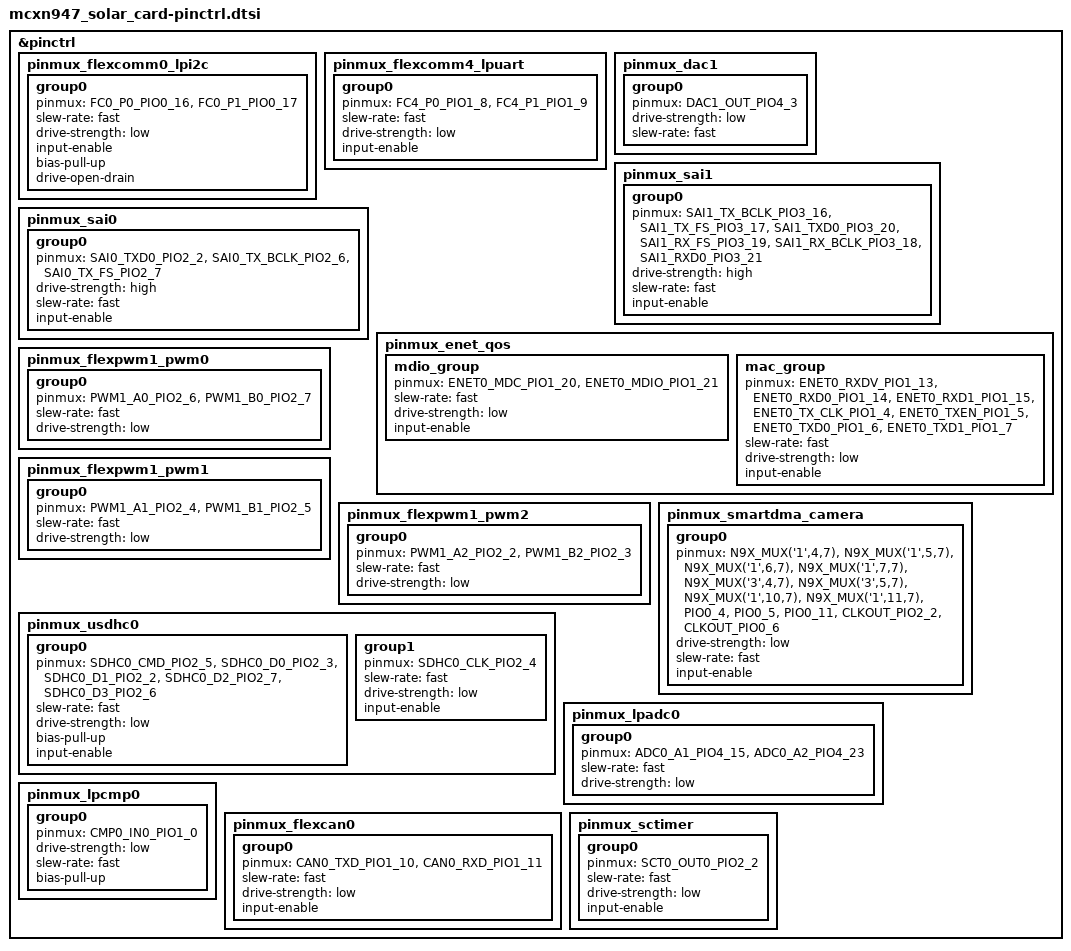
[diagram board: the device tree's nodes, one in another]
/*
 * Copyright 2024 NXP
 * SPDX-License-Identifier: Apache-2.0
 */


#include <nxp/mcx/MCXN947VDF-pinctrl.h>

&pinctrl {
	pinmux_flexcomm0_lpi2c: pinmux_flexcomm0_lpi2c {
		group0 {
			pinmux = <FC0_P0_PIO0_16>,
				<FC0_P1_PIO0_17>;
			slew-rate = "fast";
			drive-strength = "low";
			input-enable;
			bias-pull-up;
			drive-open-drain;
		};
	};

	pinmux_flexcomm4_lpuart: pinmux_flexcomm4_lpuart {
		group0 {
			pinmux = <FC4_P0_PIO1_8>,
				<FC4_P1_PIO1_9>;
			slew-rate = "fast";
			drive-strength = "low";
			input-enable;
		};
	};

	pinmux_dac1: pinmux_dac1 {
		group0 {
			pinmux = <DAC1_OUT_PIO4_3>;
			drive-strength = "low";
			slew-rate = "fast";
		};
	};

	pinmux_sai1: pinmux_sai1 {
		group0 {
			pinmux = <SAI1_TX_BCLK_PIO3_16>,
				<SAI1_TX_FS_PIO3_17>,
				<SAI1_TXD0_PIO3_20>,
				<SAI1_RX_FS_PIO3_19>,
				<SAI1_RX_BCLK_PIO3_18>,
				<SAI1_RXD0_PIO3_21>;
			drive-strength = "high";
			slew-rate = "fast";
			input-enable;
		};
	};

	pinmux_sai0: pinmux_sai0 {
		group0 {
			pinmux = <SAI0_TXD0_PIO2_2>,
				<SAI0_TX_BCLK_PIO2_6>,
				<SAI0_TX_FS_PIO2_7>;
			drive-strength = "high";
			slew-rate = "fast";
			input-enable;
		};
	};

	pinmux_enet_qos: pinmux_enet_qos {
		mdio_group {
			pinmux = <ENET0_MDC_PIO1_20>,
				<ENET0_MDIO_PIO1_21>;
			slew-rate = "fast";
			drive-strength = "low";
			input-enable;
		};
		mac_group {
			pinmux = <ENET0_RXDV_PIO1_13>,
				<ENET0_RXD0_PIO1_14>,
				<ENET0_RXD1_PIO1_15>,
				<ENET0_TX_CLK_PIO1_4>,
				<ENET0_TXEN_PIO1_5>,
				<ENET0_TXD0_PIO1_6>,
				<ENET0_TXD1_PIO1_7>;
			slew-rate = "fast";
			drive-strength = "low";
			input-enable;
		};
	};

	pinmux_flexpwm1_pwm0: pinmux_flexpwm1_pwm0 {
		group0 {
			pinmux = <PWM1_A0_PIO2_6>,
				<PWM1_B0_PIO2_7>;
			slew-rate = "fast";
			drive-strength = "low";
		};
	};

	pinmux_flexpwm1_pwm1: pinmux_flexpwm1_pwm1 {
		group0 {
			pinmux = <PWM1_A1_PIO2_4>,
				<PWM1_B1_PIO2_5>;
			slew-rate = "fast";
			drive-strength = "low";
		};
	};

	pinmux_flexpwm1_pwm2: pinmux_flexpwm1_pwm2 {
		group0 {
			pinmux = <PWM1_A2_PIO2_2>,
				<PWM1_B2_PIO2_3>;
			slew-rate = "fast";
			drive-strength = "low";
		};
	};

	pinmux_smartdma_camera: pinmux_smartdma_camera {
		group0 {
			/*
			 * SmartDMA pinmux is not defined by SOC header, so
			 * we encode it manually
			 */
			pinmux = <N9X_MUX('1',4,7)>,
				<N9X_MUX('1',5,7)>,
				<N9X_MUX('1',6,7)>,
				<N9X_MUX('1',7,7)>,
				<N9X_MUX('3',4,7)>,
				<N9X_MUX('3',5,7)>,
				<N9X_MUX('1',10,7)>,
				<N9X_MUX('1',11,7)>,
				<PIO0_4>,
				<PIO0_5>,
				<PIO0_11>,
				<CLKOUT_PIO2_2>,
				<CLKOUT_PIO0_6>;
			drive-strength = "low";
			slew-rate = "fast";
			input-enable;
		};
	};

	pinmux_usdhc0: pinmux_usdhc0 {
		group0 {
			pinmux = <SDHC0_CMD_PIO2_5>,
			       <SDHC0_D0_PIO2_3>,
			       <SDHC0_D1_PIO2_2>,
			       <SDHC0_D2_PIO2_7>,
			       <SDHC0_D3_PIO2_6>;
			slew-rate = "fast";
			drive-strength = "low";
			bias-pull-up;
			input-enable;
		};
		group1 {
			pinmux = <SDHC0_CLK_PIO2_4>;
			slew-rate = "fast";
			drive-strength = "low";
			input-enable;
		};
	};

	pinmux_lpadc0: pinmux_lpadc0 {
		group0 {
			pinmux = <ADC0_A1_PIO4_15>,
                     <ADC0_A2_PIO4_23>;
			slew-rate = "fast";
			drive-strength = "low";
		};
	};

	pinmux_lpcmp0: pinmux_lpcmp0 {
		group0 {
			pinmux = <CMP0_IN0_PIO1_0>;
			drive-strength = "low";
			slew-rate = "fast";
			bias-pull-up;
		};
	};

	pinmux_flexcan0: pinmux_flexcan0 {
		group0 {
			pinmux = <CAN0_TXD_PIO1_10>,
				<CAN0_RXD_PIO1_11>;
			slew-rate = "fast";
			drive-strength = "low";
			input-enable;
		};
	};

	pinmux_sctimer: pinmux_sctimer {
		group0 {
			pinmux = <SCT0_OUT0_PIO2_2>;
			slew-rate = "fast";
			drive-strength = "low";
			input-enable;
		};
	};
};
